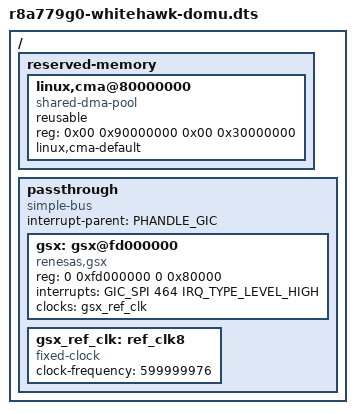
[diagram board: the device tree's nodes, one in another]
/dts-v1/;

#include <dt-bindings/interrupt-controller/arm-gic.h>
#include <dt-bindings/gpio/gpio.h>
#define PHANDLE_GIC (65000)
#define PHANDLE_ITS (64999)

/ {

	#address-cells = <2>;
	#size-cells = <2>;

	reserved-memory {
		#address-cells = <0x02>;
		#size-cells = <0x02>;
		ranges;

		linux,cma@80000000 {
			compatible = "shared-dma-pool";
			reusable;
			reg = <0x00 0x90000000 0x00 0x30000000>;
			linux,cma-default;
		};		

	};
	passthrough {
		interrupt-parent = <PHANDLE_GIC>;
		compatible = "simple-bus";
		ranges;
		#address-cells = <2>;
		#size-cells = <2>;

		gsx: gsx@fd000000 {
			compatible = "renesas,gsx";
			reg = <0 0xfd000000 0 0x80000>;
			interrupts = <GIC_SPI 464 IRQ_TYPE_LEVEL_HIGH>;
			status = "okay";
			clocks = <&gsx_ref_clk>;
			// power-domains = <&sysc R8A779G0_PD_A23DGB>;
			// resets = <&cpg 0>;
		};
		gsx_ref_clk: ref_clk8 {
			compatible = "fixed-clock";
			#clock-cells = <0>;
			clock-frequency = <599999976>;
		};
	};
};
